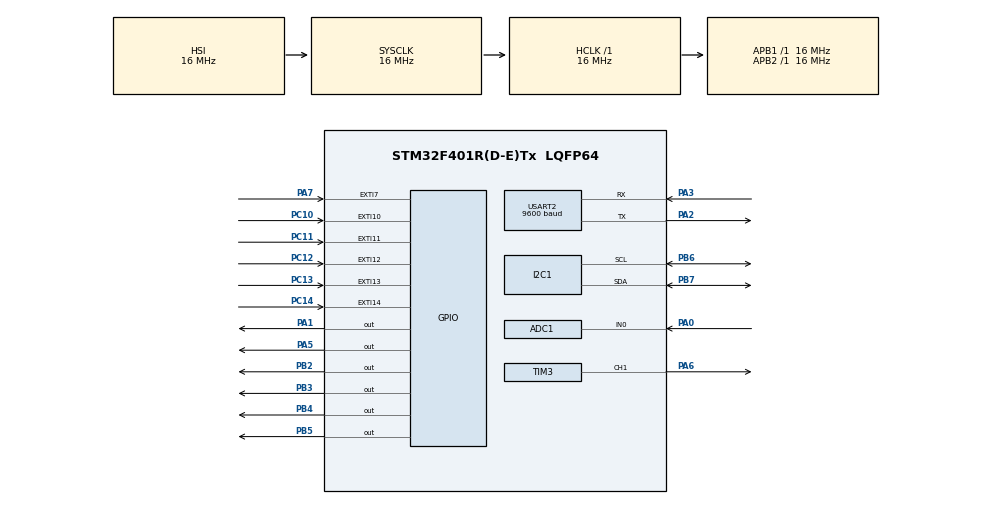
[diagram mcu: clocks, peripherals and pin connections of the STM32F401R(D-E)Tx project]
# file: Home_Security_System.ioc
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ADC1.Channel-0\#ChannelRegularConversion=ADC_CHANNEL_0
ADC1.NbrOfConversionFlag=1
ADC1.Rank-0\#ChannelRegularConversion=1
ADC1.SamplingTime-0\#ChannelRegularConversion=ADC_SAMPLETIME_3CYCLES
ADC1.master=1
Dma.ADC1.4.Direction=DMA_PERIPH_TO_MEMORY
Dma.ADC1.4.FIFOMode=DMA_FIFOMODE_DISABLE
Dma.ADC1.4.Instance=DMA2_Stream0
Dma.ADC1.4.MemDataAlignment=DMA_MDATAALIGN_HALFWORD
Dma.ADC1.4.MemInc=DMA_MINC_ENABLE
Dma.ADC1.4.Mode=DMA_NORMAL
Dma.ADC1.4.PeriphDataAlignment=DMA_PDATAALIGN_HALFWORD
Dma.ADC1.4.PeriphInc=DMA_PINC_DISABLE
Dma.ADC1.4.Priority=DMA_PRIORITY_LOW
Dma.I2C1_RX.2.Direction=DMA_PERIPH_TO_MEMORY
Dma.I2C1_RX.2.FIFOMode=DMA_FIFOMODE_DISABLE
Dma.I2C1_RX.2.Instance=DMA1_Stream0
Dma.I2C1_RX.2.MemDataAlignment=DMA_MDATAALIGN_BYTE
Dma.I2C1_RX.2.MemInc=DMA_MINC_ENABLE
Dma.I2C1_RX.2.Mode=DMA_NORMAL
Dma.I2C1_RX.2.PeriphDataAlignment=DMA_PDATAALIGN_BYTE
Dma.I2C1_RX.2.PeriphInc=DMA_PINC_DISABLE
Dma.I2C1_RX.2.Priority=DMA_PRIORITY_LOW
Dma.I2C1_TX.3.Direction=DMA_MEMORY_TO_PERIPH
Dma.I2C1_TX.3.FIFOMode=DMA_FIFOMODE_DISABLE
Dma.I2C1_TX.3.Instance=DMA1_Stream7
Dma.I2C1_TX.3.MemDataAlignment=DMA_MDATAALIGN_BYTE
Dma.I2C1_TX.3.MemInc=DMA_MINC_ENABLE
Dma.I2C1_TX.3.Mode=DMA_NORMAL
Dma.I2C1_TX.3.PeriphDataAlignment=DMA_PDATAALIGN_BYTE
Dma.I2C1_TX.3.PeriphInc=DMA_PINC_DISABLE
Dma.I2C1_TX.3.Priority=DMA_PRIORITY_LOW
Dma.Request0=USART2_RX
Dma.Request1=USART2_TX
Dma.Request2=I2C1_RX
Dma.Request3=I2C1_TX
Dma.Request4=ADC1
Dma.USART2_RX.0.Direction=DMA_PERIPH_TO_MEMORY
Dma.USART2_RX.0.FIFOMode=DMA_FIFOMODE_DISABLE
Dma.USART2_RX.0.Instance=DMA1_Stream5
Dma.USART2_RX.0.MemDataAlignment=DMA_MDATAALIGN_BYTE
Dma.USART2_RX.0.MemInc=DMA_MINC_ENABLE
Dma.USART2_RX.0.Mode=DMA_NORMAL
Dma.USART2_RX.0.PeriphDataAlignment=DMA_PDATAALIGN_BYTE
Dma.USART2_RX.0.PeriphInc=DMA_PINC_DISABLE
Dma.USART2_RX.0.Priority=DMA_PRIORITY_LOW
Dma.USART2_TX.1.Direction=DMA_MEMORY_TO_PERIPH
Dma.USART2_TX.1.FIFOMode=DMA_FIFOMODE_DISABLE
Dma.USART2_TX.1.Instance=DMA1_Stream6
Dma.USART2_TX.1.MemDataAlignment=DMA_MDATAALIGN_BYTE
Dma.USART2_TX.1.MemInc=DMA_MINC_ENABLE
Dma.USART2_TX.1.Mode=DMA_NORMAL
Dma.USART2_TX.1.PeriphDataAlignment=DMA_PDATAALIGN_BYTE
Dma.USART2_TX.1.PeriphInc=DMA_PINC_DISABLE
Dma.USART2_TX.1.Priority=DMA_PRIORITY_LOW
Mcu.Family=STM32F4
Mcu.Name=STM32F401R(D-E)Tx
Mcu.Package=LQFP64
NVIC.ADC_IRQn=true\:0\:0\:false\:false\:true\:true\:true
NVIC.DMA1_Stream0_IRQn=true\:0\:0\:false\:false\:true\:false\:true
NVIC.DMA1_Stream5_IRQn=true\:0\:0\:false\:false\:true\:false\:true
NVIC.DMA1_Stream6_IRQn=true\:0\:0\:false\:false\:true\:false\:true
NVIC.DMA1_Stream7_IRQn=true\:0\:0\:false\:false\:true\:false\:true
NVIC.DMA2_Stream0_IRQn=true\:0\:0\:false\:false\:true\:false\:true
NVIC.EXTI15_10_IRQn=true\:0\:0\:false\:false\:true\:true\:true
NVIC.EXTI9_5_IRQn=true\:0\:0\:false\:false\:true\:true\:true
NVIC.PriorityGroup=NVIC_PRIORITYGROUP_4
NVIC.TIM1_TRG_COM_TIM11_IRQn=true\:0\:0\:false\:false\:true\:true\:true
NVIC.TIM1_UP_TIM10_IRQn=true\:0\:0\:false\:false\:true\:true\:true
NVIC.TIM3_IRQn=true\:0\:0\:false\:false\:true\:true\:true
NVIC.USART2_IRQn=true\:0\:0\:false\:false\:true\:true\:true
PA0-WKUP.Signal=ADCx_IN0
PA1.Signal=GPIO_Output
PA2.Mode=Asynchronous
PA2.Signal=USART2_TX
PA3.Mode=Asynchronous
PA3.Signal=USART2_RX
PA5.Signal=GPIO_Output
PA6.Signal=S_TIM3_CH1
PA7.GPIO_ModeDefaultEXTI=GPIO_MODE_IT_RISING
PA7.GPIO_PuPd=GPIO_PULLDOWN
PA7.Signal=GPXTI7
PB2.Signal=GPIO_Output
PB3.Signal=GPIO_Output
PB4.Signal=GPIO_Output
PB5.Signal=GPIO_Output
PB6.Mode=I2C
PB6.Signal=I2C1_SCL
PB7.Mode=I2C
PB7.Signal=I2C1_SDA
PC10.GPIO_ModeDefaultEXTI=GPIO_MODE_IT_RISING
PC10.GPIO_PuPd=GPIO_PULLDOWN
PC10.Signal=GPXTI10
PC11.GPIO_ModeDefaultEXTI=GPIO_MODE_IT_RISING
PC11.GPIO_PuPd=GPIO_PULLDOWN
PC11.Signal=GPXTI11
PC12.GPIO_ModeDefaultEXTI=GPIO_MODE_IT_RISING
PC12.GPIO_PuPd=GPIO_PULLDOWN
PC12.Signal=GPXTI12
PC13-ANTI_TAMP.GPIO_ModeDefaultEXTI=GPIO_MODE_IT_RISING
PC13-ANTI_TAMP.Signal=GPXTI13
PC14-OSC32_IN.GPIO_ModeDefaultEXTI=GPIO_MODE_IT_RISING
PC14-OSC32_IN.GPIO_PuPd=GPIO_PULLDOWN
PC14-OSC32_IN.Signal=GPXTI14
ProjectManager.HeapSize=0x200
ProjectManager.StackSize=0x400
ProjectManager.TargetToolchain=STM32CubeIDE
RCC.AHBFreq_Value=16000000
RCC.APB1Freq_Value=16000000
RCC.APB2Freq_Value=16000000
RCC.CortexFreq_Value=16000000
RCC.HSE_VALUE=25000000
RCC.HSI_VALUE=16000000
RCC.LSE_VALUE=32768
RCC.SYSCLKFreq_VALUE=16000000
RCC.VCOOutputFreq_Value=192000000
SH.ADCx_IN0.0=ADC1_IN0,IN0
SH.S_TIM3_CH1.0=TIM3_CH1,PWM Generation1 CH1
TIM10.Period=0
TIM10.Prescaler=15999
TIM11.Prescaler=15999
TIM3.Channel-PWM\ Generation1\ CH1=TIM_CHANNEL_1
TIM3.Prescaler=15999
USART2.BaudRate=9600
USART2.VirtualMode=VM_ASYNC
VP_TIM10_VS_ClockSourceINT.Mode=Enable_Timer
VP_TIM11_VS_ClockSourceINT.Mode=Enable_Timer
VP_TIM3_VS_ClockSourceINT.Mode=Internal
board=custom

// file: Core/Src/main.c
/* USER CODE BEGIN Header */
/**
  ******************************************************************************
  * @file           : main.c
  * @brief          : Main program body
  ******************************************************************************
  * @attention
  *
  * <h2><center>&copy; Copyright (c) 2020 STMicroelectronics.
  * All rights reserved.</center></h2>
  *
  * This software component is licensed by ST under BSD 3-Clause license,
  * the "License"; You may not use this file except in compliance with the
  * License. You may obtain a copy of the License at:
  *                        opensource.org/licenses/BSD-3-Clause
  *
  ******************************************************************************
  */
/* USER CODE END Header */

#include "main.h"
#include "adc.h"
#include "dma.h"
#include "i2c.h"
#include "tim.h"
#include "usart.h"
#include "gpio.h"

/* USER CODE BEGIN Includes */
#include "system.h"
#include "system_configuration.h"
#include "ds1307rtc.h"
#include "uart_handler.h"
/* USER CODE END Includes */

void SystemClock_Config(void);

int main(void)
{

  /* MCU Configuration--------------------------------------------------------*/

  /* Reset of all peripherals, Initializes the Flash interface and the Systick. */
  HAL_Init();

  /* Configure the system clock */
  SystemClock_Config();

  /* Initialize all configured peripherals */
  MX_GPIO_Init();
  MX_DMA_Init();
  MX_TIM10_Init();
  MX_USART2_UART_Init();
  MX_ADC1_Init();
  MX_I2C1_Init();
  MX_TIM3_Init();
  MX_TIM11_Init();

  /* Infinite loop */
  /* USER CODE BEGIN WHILE */

  uart_handler_init(&huart2);

  system_configuration_t configuration;

  rtc_t rtc;

  ds1307rtc_init(&rtc, &hi2c1);

  init_protocol(&configuration, &htim10, &rtc);

  configuration_protocol();

  HAL_Delay(1000);

  ds1307rtc_update_date_time(&rtc);

  while (1)
  {
    /* USER CODE END WHILE */

  }
}

void SystemClock_Config(void)
{
  RCC_OscInitTypeDef RCC_OscInitStruct = {0};
  RCC_ClkInitTypeDef RCC_ClkInitStruct = {0};

  /** Configure the main internal regulator output voltage
  */
  __HAL_RCC_PWR_CLK_ENABLE();
  __HAL_PWR_VOLTAGESCALING_CONFIG(PWR_REGULATOR_VOLTAGE_SCALE2);
  /** Initializes the CPU, AHB and APB busses clocks
  */
  RCC_OscInitStruct.OscillatorType = RCC_OSCILLATORTYPE_HSI;
  RCC_OscInitStruct.HSIState = RCC_HSI_ON;
  RCC_OscInitStruct.HSICalibrationValue = RCC_HSICALIBRATION_DEFAULT;
  RCC_OscInitStruct.PLL.PLLState = RCC_PLL_NONE;
  if (HAL_RCC_OscConfig(&RCC_OscInitStruct) != HAL_OK)
  {
    Error_Handler();
  }
  /** Initializes the CPU, AHB and APB busses clocks
  */
  RCC_ClkInitStruct.ClockType = RCC_CLOCKTYPE_HCLK|RCC_CLOCKTYPE_SYSCLK
                              |RCC_CLOCKTYPE_PCLK1|RCC_CLOCKTYPE_PCLK2;
  RCC_ClkInitStruct.SYSCLKSource = RCC_SYSCLKSOURCE_HSI;
  RCC_ClkInitStruct.AHBCLKDivider = RCC_SYSCLK_DIV1;
  RCC_ClkInitStruct.APB1CLKDivider = RCC_HCLK_DIV1;
  RCC_ClkInitStruct.APB2CLKDivider = RCC_HCLK_DIV1;

  if (HAL_RCC_ClockConfig(&RCC_ClkInitStruct, FLASH_LATENCY_0) != HAL_OK)
  {
    Error_Handler();
  }
}

void Error_Handler(void)
{
}

/************************ (C) COPYRIGHT STMicroelectronics *****END OF FILE****/
